# MSS_ECC_AGGA register map
Vendor: Texas Instruments
Peripheral module from a debugger description file (folder awr2544).
Registers are 32-bit, read-write, no defined reset value unless marked. A register's access mark holds for its fields unless they carry their own. Offsets are as the file gives them; lines under a group give offsets from that group; [hi:lo] are bit positions; {n}, {i} and the like mark numbered series; 'fields as' and 'values as' point back to an identical list; <NAME> marks a mode.

## MSS_ECC_AGGA
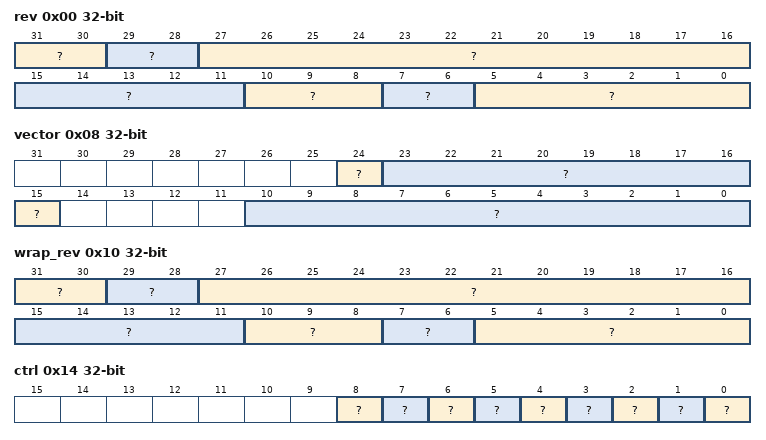
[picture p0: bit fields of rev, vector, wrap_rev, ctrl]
0x00 rev ro — Revision parameters
  [31:30] ? — Scheme
  [29:28] ? — bu
  [27:16] ? — Module ID
  [15:11] ? — RTL version
  [10:8] ? — Major version
  [7:6] ? — Custom version
  [5:0] ? — Minor version
0x08 vector access per field — ECC Vector Register
  [24] ? ro — Status to indicate if read on serial VBUS is complete
  [23:16] ? rw — Read address
  [15] ? rw — Write 1 to trigger a read on the serial VBUS
  [10:0] ? rw — Value written to select the corresponding ECC RAM for control or status
0x0C stat ro — Misc Status
  [10:0] ? — Indicates the number of RAMS serviced by the ECC aggregator
0x10 wrap_rev ro — Revision parameters
  fields as rev
0x14 ctrl — ECC Control Register
  [8] ? — check for svbus timeout errors
  [7] ? — check for parity errors
  [6] ? — Force Error only once
  [5] ? — Force Error on any RAM read
  [4] ? — Force Double Bit Error
  [3] ? — Force Single Bit Error
  [2] ? — Enable rmw
  [1] ? — Enable ECC check
  [0] ? — Enable ECC
0x18 err_ctrl1 — ECC Error Control1 Register
  [31:0] ? — Row address where single or double-bit error needs to be applied. This is ignored if force_n_row is set
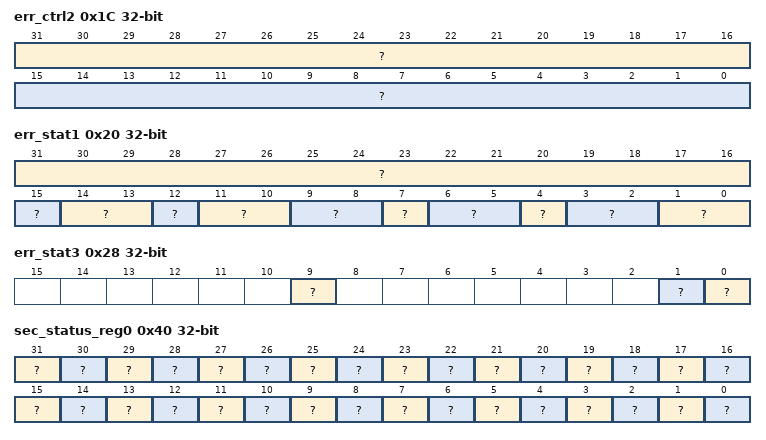
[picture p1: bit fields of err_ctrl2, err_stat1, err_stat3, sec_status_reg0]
0x1C err_ctrl2 — ECC Error Control2 Register
  [31:16] ? — Data bit that needs to be flipped if double bit error needs to be forced
  [15:0] ? — Data bit that needs to be flipped when force_sec is set
0x20 err_stat1 access per field — ECC Error Status1 Register
  [31:16] ? ro — Data bit that corresponds to the single-bit error
  [15] ? rw — Clear control reg error Error Status, you must also re write the contorl ergister itself to clear this
  [14:13] ? rw — Clear parity Error Status
  [12] ? rw — Clear other Error Status
  [11:10] ? rw — Clear Double Bit Error Status
  [9:8] ? rw — Clear Single Bit Error Status
  [7] ? rw — control register error pending, Level interrupt
  [6:5] ? rw — Level parity error Error Status
  [4] ? rw — successive single-bit errors have occurred while a writeback is still pending, Level interrupt
  [3:2] ? rw — Level Double Bit Error Status
  [1:0] ? rw — Level Single Bit Error Status
0x24 err_stat2 ro — ECC Error Status2 Register
  [31:0] ? — Row address where the single or double-bit error has occurred
0x28 err_stat3 access per field — ECC Error Status3 Register
  [9] ? rw — Clear svbus timeout Error Status
  [1] ? rw — Level svbus timeout error Error Status
  [0] ? ro — delayed write back pending Status
0x3C sec_eoi_reg — EOI Register
  [0] ?
0x40 sec_status_reg0 — Interrupt Status Register 0
  [31] ? — Interrupt Pending Status for b0tcm1_bank1_pend
  [30] ? — Interrupt Pending Status for b0tcm1_bank0_pend
  [29] ? — Interrupt Pending Status for atcm1_bank1_pend
  [28] ? — Interrupt Pending Status for atcm1_bank0_pend
  [27] ? — Interrupt Pending Status for cpu0_ks_vim_ramecc_pend
  [26] ? — Interrupt Pending Status for b1tcm0_bank1_pend
  [25] ? — Interrupt Pending Status for b1tcm0_bank0_pend
  [24] ? — Interrupt Pending Status for b0tcm0_bank1_pend
  [23] ? — Interrupt Pending Status for b0tcm0_bank0_pend
  [22] ? — Interrupt Pending Status for atcm0_bank1_pend
  [21] ? — Interrupt Pending Status for atcm0_bank0_pend
  [20] ? — Interrupt Pending Status for cpu0_ddata_ram7_pend
  [19] ? — Interrupt Pending Status for cpu0_ddata_ram6_pend
  [18] ? — Interrupt Pending Status for cpu0_ddata_ram5_pend
  [17] ? — Interrupt Pending Status for cpu0_ddata_ram4_pend
  [16] ? — Interrupt Pending Status for cpu0_ddata_ram3_pend
  [15] ? — Interrupt Pending Status for cpu0_ddata_ram2_pend
  [14] ? — Interrupt Pending Status for cpu0_ddata_ram1_pend
  [13] ? — Interrupt Pending Status for cpu0_ddata_ram0_pend
  [12] ? — Interrupt Pending Status for cpu0_ddirty_ram_pend
  [11] ? — Interrupt Pending Status for cpu0_dtag_ram3_pend
  [10] ? — Interrupt Pending Status for cpu0_dtag_ram2_pend
  [9] ? — Interrupt Pending Status for cpu0_dtag_ram1_pend
  [8] ? — Interrupt Pending Status for cpu0_dtag_ram0_pend
  [7] ? — Interrupt Pending Status for cpu0_idata_bank3_pend
  [6] ? — Interrupt Pending Status for cpu0_idata_bank2_pend
  [5] ? — Interrupt Pending Status for cpu0_idata_bank1_pend
  [4] ? — Interrupt Pending Status for cpu0_idata_bank0_pend
  [3] ? — Interrupt Pending Status for cpu0_itag_ram3_pend
  [2] ? — Interrupt Pending Status for cpu0_itag_ram2_pend
  [1] ? — Interrupt Pending Status for cpu0_itag_ram1_pend
  [0] ? — Interrupt Pending Status for cpu0_itag_ram0_pend
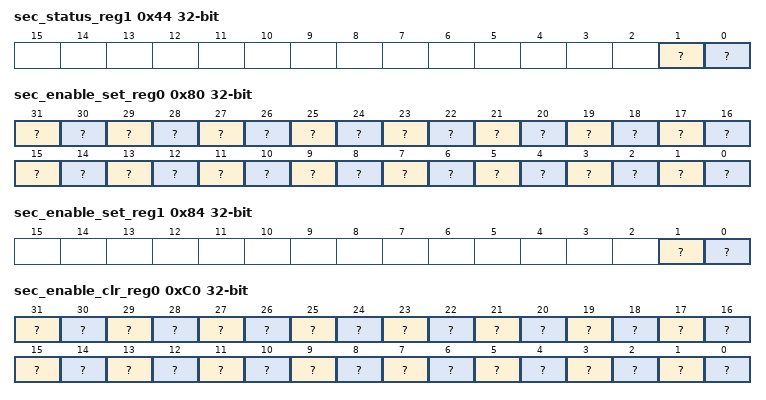
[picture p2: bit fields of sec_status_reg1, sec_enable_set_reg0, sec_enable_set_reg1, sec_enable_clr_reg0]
0x44 sec_status_reg1 — Interrupt Status Register 1
  [1] ? — Interrupt Pending Status for b1tcm1_bank1_pend
  [0] ? — Interrupt Pending Status for b1tcm1_bank0_pend
0x80 sec_enable_set_reg0 — Interrupt Enable Set Register 0
  [31] ? — Interrupt Enable Set Register for b0tcm1_bank1_pend
  [30] ? — Interrupt Enable Set Register for b0tcm1_bank0_pend
  [29] ? — Interrupt Enable Set Register for atcm1_bank1_pend
  [28] ? — Interrupt Enable Set Register for atcm1_bank0_pend
  [27] ? — Interrupt Enable Set Register for cpu0_ks_vim_ramecc_pend
  [26] ? — Interrupt Enable Set Register for b1tcm0_bank1_pend
  [25] ? — Interrupt Enable Set Register for b1tcm0_bank0_pend
  [24] ? — Interrupt Enable Set Register for b0tcm0_bank1_pend
  [23] ? — Interrupt Enable Set Register for b0tcm0_bank0_pend
  [22] ? — Interrupt Enable Set Register for atcm0_bank1_pend
  [21] ? — Interrupt Enable Set Register for atcm0_bank0_pend
  [20] ? — Interrupt Enable Set Register for cpu0_ddata_ram7_pend
  [19] ? — Interrupt Enable Set Register for cpu0_ddata_ram6_pend
  [18] ? — Interrupt Enable Set Register for cpu0_ddata_ram5_pend
  [17] ? — Interrupt Enable Set Register for cpu0_ddata_ram4_pend
  [16] ? — Interrupt Enable Set Register for cpu0_ddata_ram3_pend
  [15] ? — Interrupt Enable Set Register for cpu0_ddata_ram2_pend
  [14] ? — Interrupt Enable Set Register for cpu0_ddata_ram1_pend
  [13] ? — Interrupt Enable Set Register for cpu0_ddata_ram0_pend
  [12] ? — Interrupt Enable Set Register for cpu0_ddirty_ram_pend
  [11] ? — Interrupt Enable Set Register for cpu0_dtag_ram3_pend
  [10] ? — Interrupt Enable Set Register for cpu0_dtag_ram2_pend
  [9] ? — Interrupt Enable Set Register for cpu0_dtag_ram1_pend
  [8] ? — Interrupt Enable Set Register for cpu0_dtag_ram0_pend
  [7] ? — Interrupt Enable Set Register for cpu0_idata_bank3_pend
  [6] ? — Interrupt Enable Set Register for cpu0_idata_bank2_pend
  [5] ? — Interrupt Enable Set Register for cpu0_idata_bank1_pend
  [4] ? — Interrupt Enable Set Register for cpu0_idata_bank0_pend
  [3] ? — Interrupt Enable Set Register for cpu0_itag_ram3_pend
  [2] ? — Interrupt Enable Set Register for cpu0_itag_ram2_pend
  [1] ? — Interrupt Enable Set Register for cpu0_itag_ram1_pend
  [0] ? — Interrupt Enable Set Register for cpu0_itag_ram0_pend
0x84 sec_enable_set_reg1 — Interrupt Enable Set Register 1
  [1] ? — Interrupt Enable Set Register for b1tcm1_bank1_pend
  [0] ? — Interrupt Enable Set Register for b1tcm1_bank0_pend
0xC0 sec_enable_clr_reg0 — Interrupt Enable Clear Register 0
  [31] ? — Interrupt Enable Clear Register for b0tcm1_bank1_pend
  [30] ? — Interrupt Enable Clear Register for b0tcm1_bank0_pend
  [29] ? — Interrupt Enable Clear Register for atcm1_bank1_pend
  [28] ? — Interrupt Enable Clear Register for atcm1_bank0_pend
  [27] ? — Interrupt Enable Clear Register for cpu0_ks_vim_ramecc_pend
  [26] ? — Interrupt Enable Clear Register for b1tcm0_bank1_pend
  [25] ? — Interrupt Enable Clear Register for b1tcm0_bank0_pend
  [24] ? — Interrupt Enable Clear Register for b0tcm0_bank1_pend
  [23] ? — Interrupt Enable Clear Register for b0tcm0_bank0_pend
  [22] ? — Interrupt Enable Clear Register for atcm0_bank1_pend
  [21] ? — Interrupt Enable Clear Register for atcm0_bank0_pend
  [20] ? — Interrupt Enable Clear Register for cpu0_ddata_ram7_pend
  [19] ? — Interrupt Enable Clear Register for cpu0_ddata_ram6_pend
  [18] ? — Interrupt Enable Clear Register for cpu0_ddata_ram5_pend
  [17] ? — Interrupt Enable Clear Register for cpu0_ddata_ram4_pend
  [16] ? — Interrupt Enable Clear Register for cpu0_ddata_ram3_pend
  [15] ? — Interrupt Enable Clear Register for cpu0_ddata_ram2_pend
  [14] ? — Interrupt Enable Clear Register for cpu0_ddata_ram1_pend
  [13] ? — Interrupt Enable Clear Register for cpu0_ddata_ram0_pend
  [12] ? — Interrupt Enable Clear Register for cpu0_ddirty_ram_pend
  [11] ? — Interrupt Enable Clear Register for cpu0_dtag_ram3_pend
  [10] ? — Interrupt Enable Clear Register for cpu0_dtag_ram2_pend
  [9] ? — Interrupt Enable Clear Register for cpu0_dtag_ram1_pend
  [8] ? — Interrupt Enable Clear Register for cpu0_dtag_ram0_pend
  [7] ? — Interrupt Enable Clear Register for cpu0_idata_bank3_pend
  [6] ? — Interrupt Enable Clear Register for cpu0_idata_bank2_pend
  [5] ? — Interrupt Enable Clear Register for cpu0_idata_bank1_pend
  [4] ? — Interrupt Enable Clear Register for cpu0_idata_bank0_pend
  [3] ? — Interrupt Enable Clear Register for cpu0_itag_ram3_pend
  [2] ? — Interrupt Enable Clear Register for cpu0_itag_ram2_pend
  [1] ? — Interrupt Enable Clear Register for cpu0_itag_ram1_pend
  [0] ? — Interrupt Enable Clear Register for cpu0_itag_ram0_pend
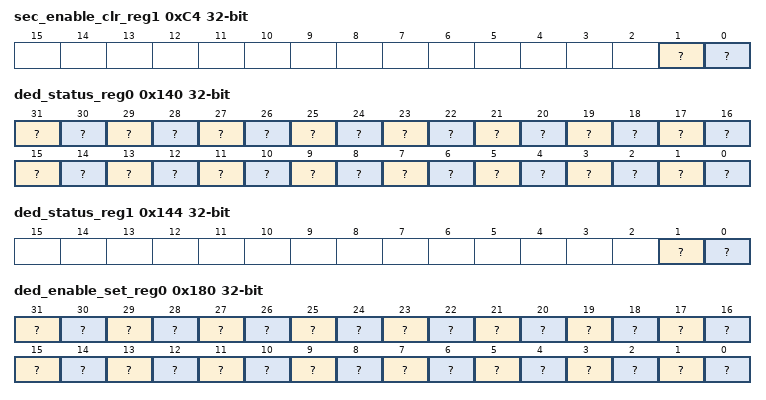
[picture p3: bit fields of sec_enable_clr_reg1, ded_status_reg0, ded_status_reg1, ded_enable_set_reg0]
0xC4 sec_enable_clr_reg1 — Interrupt Enable Clear Register 1
  [1] ? — Interrupt Enable Clear Register for b1tcm1_bank1_pend
  [0] ? — Interrupt Enable Clear Register for b1tcm1_bank0_pend
0x13C ded_eoi_reg — EOI Register
  [0] ?
0x140 ded_status_reg0 — Interrupt Status Register 0
  fields as sec_status_reg0
0x144 ded_status_reg1 — Interrupt Status Register 1
  fields as sec_status_reg1
0x180 ded_enable_set_reg0 — Interrupt Enable Set Register 0
  fields as sec_enable_set_reg0
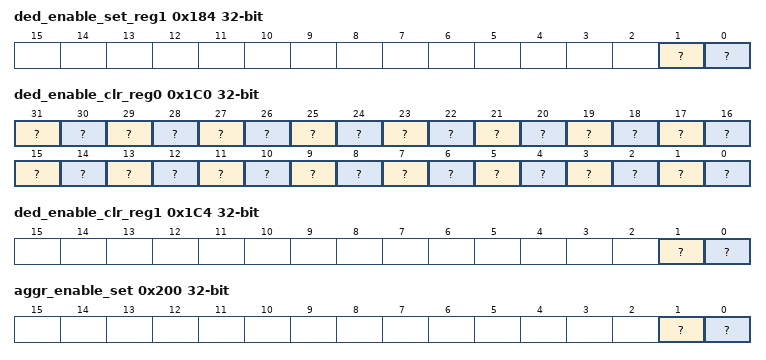
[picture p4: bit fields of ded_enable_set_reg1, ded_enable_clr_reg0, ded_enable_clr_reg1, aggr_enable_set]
0x184 ded_enable_set_reg1 — Interrupt Enable Set Register 1
  fields as sec_enable_set_reg1
0x1C0 ded_enable_clr_reg0 — Interrupt Enable Clear Register 0
  fields as sec_enable_clr_reg0
0x1C4 ded_enable_clr_reg1 — Interrupt Enable Clear Register 1
  fields as sec_enable_clr_reg1
0x200 aggr_enable_set — AGGR interrupt enable set Register
  [1] ? — interrupt enable set for svbus timeout errors
  [0] ? — interrupt enable set for parity errors
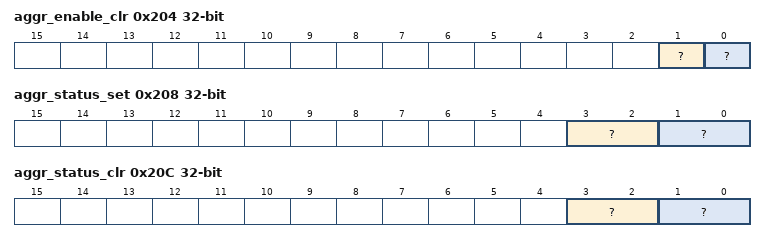
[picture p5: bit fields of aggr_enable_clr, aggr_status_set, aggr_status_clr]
0x204 aggr_enable_clr — AGGR interrupt enable clear Register
  [1] ? — interrupt enable clear for svbus timeout errors
  [0] ? — interrupt enable clear for parity errors
0x208 aggr_status_set — AGGR interrupt status set Register
  [3:2] ? — interrupt status set for svbus timeout errors
  [1:0] ? — interrupt status set for parity errors
0x20C aggr_status_clr — AGGR interrupt status clear Register
  [3:2] ? — interrupt status clear for svbus timeout errors
  [1:0] ? — interrupt status clear for parity errors
